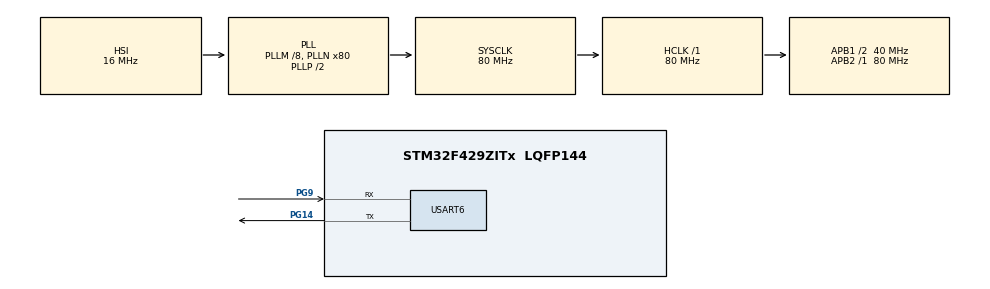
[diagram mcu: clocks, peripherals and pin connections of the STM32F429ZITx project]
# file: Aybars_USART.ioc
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Mcu.Family=STM32F4
Mcu.Name=STM32F429ZITx
Mcu.Package=LQFP144
NVIC.PriorityGroup=NVIC_PRIORITYGROUP_4
PC14/OSC32_IN.Mode=LSE-External-Oscillator
PC14/OSC32_IN.Signal=RCC_OSC32_IN
PC15/OSC32_OUT.Mode=LSE-External-Oscillator
PC15/OSC32_OUT.Signal=RCC_OSC32_OUT
PG14.Mode=Asynchronous
PG14.Signal=USART6_TX
PG9.Mode=Asynchronous
PG9.Signal=USART6_RX
PH0/OSC_IN.Mode=HSE-External-Oscillator
PH0/OSC_IN.Signal=RCC_OSC_IN
PH1/OSC_OUT.Mode=HSE-External-Oscillator
PH1/OSC_OUT.Signal=RCC_OSC_OUT
ProjectManager.HeapSize=0x200
ProjectManager.StackSize=0x400
ProjectManager.TargetToolchain=STM32CubeIDE
RCC.48MHZClocksFreq_Value=40000000
RCC.AHBFreq_Value=80000000
RCC.APB1CLKDivider=RCC_HCLK_DIV2
RCC.APB1Freq_Value=40000000
RCC.APB1TimFreq_Value=80000000
RCC.APB2Freq_Value=80000000
RCC.APB2TimFreq_Value=80000000
RCC.CortexFreq_Value=80000000
RCC.HCLKFreq_Value=80000000
RCC.HSE_VALUE=25000000
RCC.HSI_VALUE=16000000
RCC.PLLM=8
RCC.PLLN=80
RCC.SYSCLKFreq_VALUE=80000000
RCC.SYSCLKSource=RCC_SYSCLKSOURCE_PLLCLK
RCC.VCOOutputFreq_Value=160000000
USART6.VirtualMode=VM_ASYNC
board=custom

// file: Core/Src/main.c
/* USER CODE BEGIN Header */
/**
  ******************************************************************************
  * @file           : main.c
  * @brief          : Main program body
  ******************************************************************************
  * @attention
  *
  * <h2><center>&copy; Copyright (c) 2021 STMicroelectronics.
  * All rights reserved.</center></h2>
  *
  * This software component is licensed by ST under BSD 3-Clause license,
  * the "License"; You may not use this file except in compliance with the
  * License. You may obtain a copy of the License at:
  *                        opensource.org/licenses/BSD-3-Clause
  *
  ******************************************************************************
  */
/* USER CODE END Header */
#include "main.h"

UART_HandleTypeDef huart6;

void SystemClock_Config(void);
static void MX_GPIO_Init(void);
static void MX_USART6_UART_Init(void);

int main(void)
{
  /* USER CODE BEGIN 1 */
	uint8_t MSG[35] = {'\0'};
	uint8_t X = 0;
  /* USER CODE END 1 */

  /* MCU Configuration--------------------------------------------------------*/

  /* Reset of all peripherals, Initializes the Flash interface and the Systick. */
  HAL_Init();

  /* Configure the system clock */
  SystemClock_Config();

  /* Initialize all configured peripherals */
  MX_GPIO_Init();
  MX_USART6_UART_Init();

  /* Infinite loop */
  /* USER CODE BEGIN WHILE */
  while (1)
  {
	  sprintf(MSG, "Hello! Tracing X = %d\n", X);
	   HAL_UART_Transmit(&huart6, MSG, sizeof(MSG), 100);
	   HAL_Delay(500);
	   X++;
    /* USER CODE END WHILE */

  }
}

void SystemClock_Config(void)
{
  RCC_OscInitTypeDef RCC_OscInitStruct = {0};
  RCC_ClkInitTypeDef RCC_ClkInitStruct = {0};

  /** Configure the main internal regulator output voltage
  */
  __HAL_RCC_PWR_CLK_ENABLE();
  __HAL_PWR_VOLTAGESCALING_CONFIG(PWR_REGULATOR_VOLTAGE_SCALE3);
  /** Initializes the RCC Oscillators according to the specified parameters
  * in the RCC_OscInitTypeDef structure.
  */
  RCC_OscInitStruct.OscillatorType = RCC_OSCILLATORTYPE_HSI;
  RCC_OscInitStruct.HSIState = RCC_HSI_ON;
  RCC_OscInitStruct.HSICalibrationValue = RCC_HSICALIBRATION_DEFAULT;
  RCC_OscInitStruct.PLL.PLLState = RCC_PLL_ON;
  RCC_OscInitStruct.PLL.PLLSource = RCC_PLLSOURCE_HSI;
  RCC_OscInitStruct.PLL.PLLM = 8;
  RCC_OscInitStruct.PLL.PLLN = 80;
  RCC_OscInitStruct.PLL.PLLP = RCC_PLLP_DIV2;
  RCC_OscInitStruct.PLL.PLLQ = 4;
  if (HAL_RCC_OscConfig(&RCC_OscInitStruct) != HAL_OK)
  {
    Error_Handler();
  }
  /** Initializes the CPU, AHB and APB buses clocks
  */
  RCC_ClkInitStruct.ClockType = RCC_CLOCKTYPE_HCLK|RCC_CLOCKTYPE_SYSCLK
                              |RCC_CLOCKTYPE_PCLK1|RCC_CLOCKTYPE_PCLK2;
  RCC_ClkInitStruct.SYSCLKSource = RCC_SYSCLKSOURCE_PLLCLK;
  RCC_ClkInitStruct.AHBCLKDivider = RCC_SYSCLK_DIV1;
  RCC_ClkInitStruct.APB1CLKDivider = RCC_HCLK_DIV2;
  RCC_ClkInitStruct.APB2CLKDivider = RCC_HCLK_DIV1;

  if (HAL_RCC_ClockConfig(&RCC_ClkInitStruct, FLASH_LATENCY_2) != HAL_OK)
  {
    Error_Handler();
  }
}

static void MX_USART6_UART_Init(void)
{

  huart6.Instance = USART6;
  huart6.Init.BaudRate = 115200;
  huart6.Init.WordLength = UART_WORDLENGTH_8B;
  huart6.Init.StopBits = UART_STOPBITS_1;
  huart6.Init.Parity = UART_PARITY_NONE;
  huart6.Init.Mode = UART_MODE_TX_RX;
  huart6.Init.HwFlowCtl = UART_HWCONTROL_NONE;
  huart6.Init.OverSampling = UART_OVERSAMPLING_16;
  if (HAL_UART_Init(&huart6) != HAL_OK)
  {
    Error_Handler();
  }

}

static void MX_GPIO_Init(void)
{

  /* GPIO Ports Clock Enable */
  __HAL_RCC_GPIOC_CLK_ENABLE();
  __HAL_RCC_GPIOH_CLK_ENABLE();
  __HAL_RCC_GPIOG_CLK_ENABLE();

}

void Error_Handler(void)
{
  __disable_irq();
  while (1)
  {
  }
}

/************************ (C) COPYRIGHT STMicroelectronics *****END OF FILE****/
